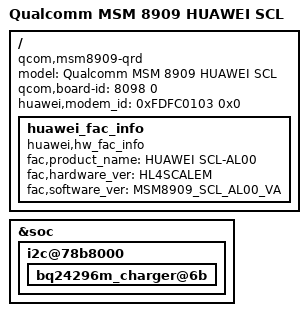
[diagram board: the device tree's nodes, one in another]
/* Copyright (c) 2014, The Linux Foundation. All rights reserved.
 *
 * This program is free software; you can redistribute it and/or modify
 * it under the terms of the GNU General Public License version 2 and
 * only version 2 as published by the Free Software Foundation.
 *
 * This program is distributed in the hope that it will be useful,
 * but WITHOUT ANY WARRANTY; without even the implied warranty of
 * MERCHANTABILITY or FITNESS FOR A PARTICULAR PURPOSE.  See the
 * GNU General Public License for more details.
 */

/dts-v1/;

#include "msm8909-qrd.dtsi"
#include "scale/msm8909-qrd-scale.dtsi"

&soc {
	i2c@78b8000{ /* BLSP1 QUP6 */
		bq24296m_charger@6b {
		status = "ok";
		};
	};
};

/ {
	model = "Qualcomm MSM 8909 HUAWEI SCL";
	compatible = "qcom,msm8909-qrd", "qcom,msm8909", "qcom,qrd";
	qcom,board-id= <8098 0>;
	huawei,modem_id = <0xFDFC0103 0x0>;
};

/ {
	huawei_fac_info {
		  compatible = "huawei,hw_fac_info";
		  fac,product_name = "HUAWEI SCL-AL00";
		  fac,hardware_ver = "HL4SCALEM";
		  fac,software_ver = "MSM8909_SCL_AL00_VA";
		  status = "ok";
	};
};
